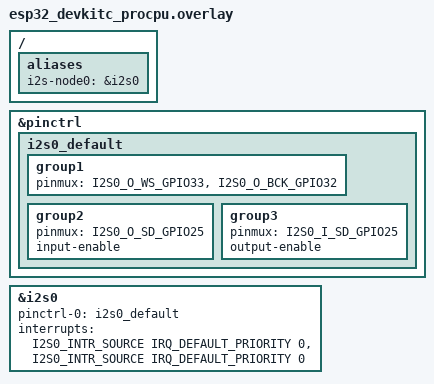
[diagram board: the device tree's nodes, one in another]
/*
 * Copyright (c) 2025 Espressif Systems (Shanghai) Co., Ltd.
 *
 * SPDX-License-Identifier: Apache-2.0
 */

/* i2s-node0 is the transmitter/receiver */

/ {
	aliases {
		i2s-node0 = &i2s0;
	};
};

&pinctrl {
	i2s0_default: i2s0_default {
		group1 {
			pinmux = <I2S0_O_WS_GPIO33>,
				<I2S0_O_BCK_GPIO32>;
		};

		group2 {
			pinmux =  <I2S0_O_SD_GPIO25>;
			input-enable;
		};

		group3 {
			pinmux = <I2S0_I_SD_GPIO25>;
			output-enable;
		};
	};
};

&i2s0 {
	status = "okay";
	pinctrl-0 = <&i2s0_default>;
	pinctrl-names = "default";

	interrupts = <I2S0_INTR_SOURCE IRQ_DEFAULT_PRIORITY 0>,
		     <I2S0_INTR_SOURCE IRQ_DEFAULT_PRIORITY 0>;
	interrupt-names = "tx", "rx";
};
